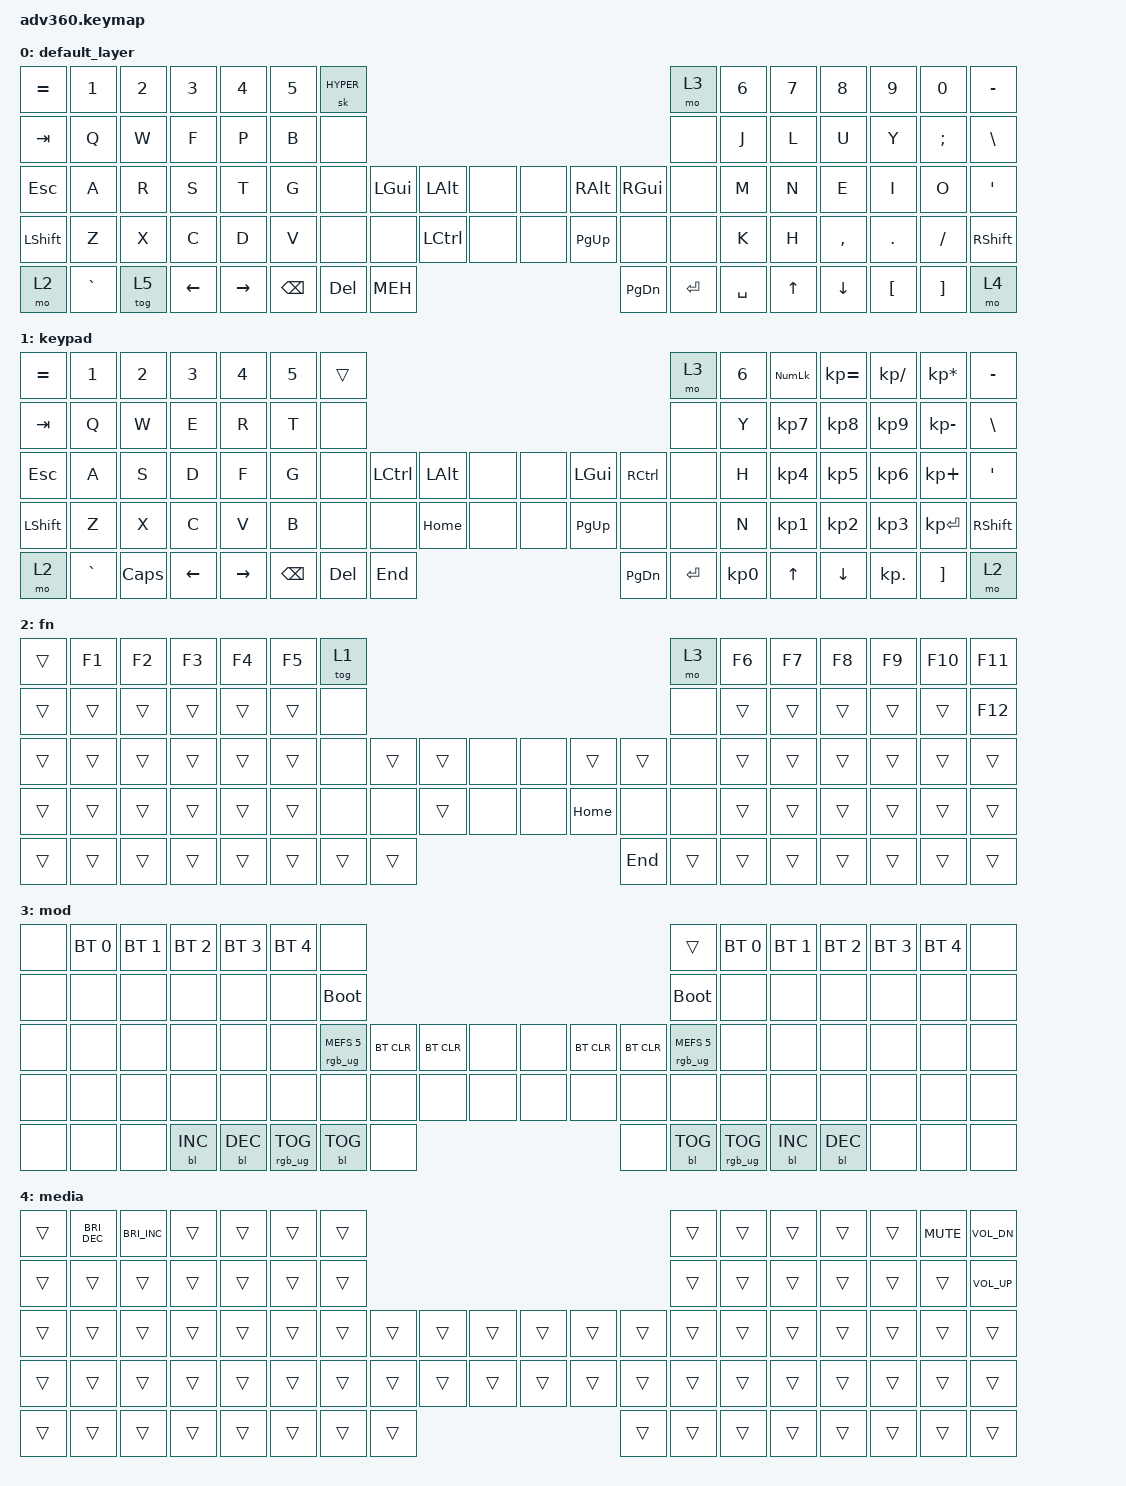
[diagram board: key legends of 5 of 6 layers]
#include <behaviors.dtsi>
#include <dt-bindings/zmk/keys.h>
#include <dt-bindings/zmk/bt.h>
#include <dt-bindings/zmk/rgb.h>
#include <dt-bindings/zmk/backlight.h>

#define MEH LC(LA(LGUI))
#define HYPER LS(LC(LA(LGUI)))

/ {
    behaviors {
      #include "macros.dtsi"

      hm: homerow_mods {
          compatible = "zmk,behavior-hold-tap";
          label = "HOMEROW_MODS";
          #binding-cells = <2>;
          tapping-term-ms = <200>;
          quick_tap_ms = <175>;
          flavor = "tap-preferred";
          bindings = <&kp>, <&kp>;
      };
    };

  keymap {
    compatible = "zmk,keymap";

    default_layer {
      bindings = <
        &kp EQUAL &kp N1    &kp N2 &kp N3   &kp N4     &kp N5 &sk HYPER                                                                        &mo 3 &kp N6 &kp N7 &kp N8    &kp N9   &kp N0        &kp MINUS
        &kp TAB   &kp Q     &kp W  &kp F    &kp P      &kp B  &none                                                                            &none &kp J  &kp L  &kp U     &kp Y    &kp SEMICOLON &kp BSLH
        &kp ESC   &kp A     &kp R  &kp S    &kp T      &kp G  &none               &kp LGUI &kp LALT  &none &none &kp RALT  &kp RGUI            &none &kp M  &kp N  &kp E     &kp I    &kp O      &kp SQT
        &kp LSHFT &kp Z     &kp X  &kp C    &kp D      &kp V            &none     &none    &kp LCTRL &none &none &kp PG_UP &none     &none           &kp K  &kp H  &kp COMMA &kp DOT  &kp FSLH      &kp RSHFT
        &mo 2     &kp GRAVE &tog 5 &kp LEFT &kp RIGHT                   &kp BSPC  &kp DEL  &kp MEH               &kp PG_DN &kp ENTER &kp SPACE              &kp UP &kp DOWN  &kp LBKT &kp RBKT      &mo 4
      >;
    };
    keypad {
      bindings = <
        &kp EQUAL &kp N1    &kp N2   &kp N3   &kp N4     &kp N5 &trans                                                                       &mo 3 &kp N6 &kp KP_NUM &kp KP_EQUAL &kp KP_DIVIDE &kp KP_MULTIPLY &kp MINUS
        &kp TAB   &kp Q     &kp W    &kp E    &kp R      &kp T  &none                                                                        &none &kp Y  &kp KP_N7  &kp KP_N8    &kp KP_N9     &kp KP_MINUS    &kp BSLH
        &kp ESC   &kp A     &kp S    &kp D    &kp F      &kp G  &none           &kp LCTRL &kp LALT &none &none &kp LGUI  &kp RCTRL           &none &kp H  &kp KP_N4  &kp KP_N5    &kp KP_N6     &kp KP_PLUS     &kp SQT
        &kp LSHFT &kp Z     &kp X    &kp C    &kp V      &kp B         &none    &none     &kp HOME &none &none &kp PG_UP &none     &none           &kp N  &kp KP_N1  &kp KP_N2    &kp KP_N3     &kp KP_ENTER    &kp RSHFT
        &mo 2     &kp GRAVE &kp CAPS &kp LEFT &kp RIGHT                &kp BSPC &kp DEL   &kp END              &kp PG_DN &kp ENTER &kp KP_N0              &kp UP     &kp DOWN     &kp KP_DOT    &kp RBKT        &mo 2
      >;
    };
    fn {
      bindings = <
        &trans &kp F1 &kp F2 &kp F3 &kp F4 &kp F5 &tog 1                                                      &mo 3 &kp F6 &kp F7 &kp F8 &kp F9  &kp F10 &kp F11
        &trans &trans &trans &trans &trans &trans &none                                                       &none &trans &trans &trans &trans  &trans  &kp F12
        &trans &trans &trans &trans &trans &trans &none        &trans &trans &none &none &trans &trans        &none &trans &trans &trans &trans  &trans  &trans
        &trans &trans &trans &trans &trans &trans       &none  &none  &trans &none &none &kp HOME &none  &none        &trans &trans &trans &trans  &trans  &trans
        &trans &trans &trans &trans &trans              &trans &trans &trans             &kp END &trans &trans              &trans &trans &trans  &trans  &trans
      >;
    };
    mod {
      bindings = <
        &none &bt BT_SEL 0 &bt BT_SEL 1 &bt BT_SEL 2 &bt BT_SEL 3 &bt BT_SEL 4 &none                                                                                                          &trans                 &bt BT_SEL 0 &bt BT_SEL 1 &bt BT_SEL 2 &bt BT_SEL 3 &bt BT_SEL 4 &none
        &none &none        &none        &none        &none        &none        &bootloader                                                                                                    &bootloader            &none        &none        &none        &none        &none        &none
        &none &none        &none        &none        &none        &none        &rgb_ug RGB_MEFS_CMD 5                 &bt BT_CLR &bt BT_CLR &none &none &bt BT_CLR &bt BT_CLR                 &rgb_ug RGB_MEFS_CMD 5 &none        &none        &none        &none        &none        &none
        &none &none        &none        &none        &none        &none                               &none           &none      &none      &none &none &none      &none      &none                                  &none        &none        &none        &none        &none        &none
        &none &none        &none        &bl BL_INC   &bl BL_DEC                                       &rgb_ug RGB_TOG &bl BL_TOG &none                  &none      &bl BL_TOG &rgb_ug RGB_TOG                                     &bl BL_INC   &bl BL_DEC   &none        &none        &none
      >;
    };
    media {
      bindings = <
        &trans &kp C_BRIGHTNESS_DEC &kp C_BRIGHTNESS_INC &trans &trans &trans &trans                                                          &trans &trans &trans &trans &trans &kp C_MUTE &kp C_VOL_DN
        &trans &trans               &trans               &trans &trans &trans &trans                                                          &trans &trans &trans &trans &trans &trans     &kp C_VOLUME_UP
        &trans &trans               &trans               &trans &trans &trans &trans        &trans &trans &trans &trans &trans &trans         &trans &trans &trans &trans &trans &trans     &trans
        &trans &trans               &trans               &trans &trans &trans        &trans &trans &trans &trans &trans &trans &trans &trans         &trans &trans &trans &trans &trans     &trans
        &trans &trans               &trans               &trans &trans               &trans &trans &trans               &trans &trans &trans                &trans &trans &trans &trans     &trans
      >;
    };
    gaming {
      bindings = <
        &trans &trans &trans &trans &trans &trans &trans                                                          &trans &trans &trans &trans &trans &trans &trans
        &trans &trans &kp Q  &kp W  &kp E  &kp R  &kp T                                                          &trans &trans &trans &trans &trans &trans &trans
        &trans &trans &kp A  &kp S  &kp D  &kp F  &kp G         &trans &trans &trans &trans &trans &trans         &trans &trans &trans &trans &trans &trans &trans
        &trans &trans &kp Z  &kp X  &kp C  &kp V  &kp B  &trans &trans &trans &trans &trans &trans &trans &trans         &trans &trans &trans &trans &trans &trans
        &trans &trans &trans &trans &trans               &trans &trans &trans               &trans &trans &trans                &trans &trans &trans &trans &trans
      >;
    };

  };
};
